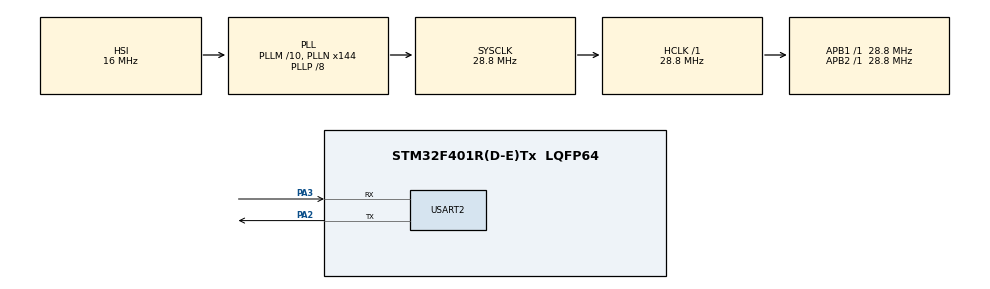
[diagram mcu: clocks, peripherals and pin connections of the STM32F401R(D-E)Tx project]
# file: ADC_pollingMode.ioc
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Mcu.Family=STM32F4
RCC.CortexFreq_Value=28800000
ADC1.Rank-0\#ChannelRegularConversion=1
VP_ADC1_TempSens_Input.Mode=IN-TempSens
ADC1.ContinuousConvMode=ENABLE
RCC.SYSCLKSource=RCC_SYSCLKSOURCE_PLLCLK
ProjectManager.StackSize=0x400
PA3.Mode=Asynchronous
ProjectManager.TargetToolchain=STM32CubeIDE
RCC.HCLKFreq_Value=28800000
RCC.APB2TimFreq_Value=28800000
RCC.LSE_VALUE=32768
RCC.AHBFreq_Value=28800000
ADC1.Channel-0\#ChannelRegularConversion=ADC_CHANNEL_TEMPSENSOR
RCC.HSE_VALUE=25000000
board=custom
RCC.VCOOutputFreq_Value=230400000
RCC.APB2Freq_Value=28800000
ADC1.NbrOfConversion=1
Mcu.Name=STM32F401R(D-E)Tx
ADC1.SamplingTime-0\#ChannelRegularConversion=ADC_SAMPLETIME_144CYCLES
PA2.Signal=USART2_TX
RCC.48MHZClocksFreq_Value=57600000
RCC.SYSCLKFreq_VALUE=28800000
Mcu.Package=LQFP64
ADC1.master=1
USART2.VirtualMode=VM_ASYNC
ProjectManager.HeapSize=0x200
RCC.HSI_VALUE=16000000
RCC.PLLP=RCC_PLLP_DIV8
NVIC.PriorityGroup=NVIC_PRIORITYGROUP_4
ADC1.NbrOfConversionFlag=1
RCC.PLLM=10
RCC.PLLN=144
RCC.APB1TimFreq_Value=28800000
PA2.Mode=Asynchronous
RCC.APB1Freq_Value=28800000
ADC1.EOCSelection=ADC_EOC_SEQ_CONV
ADC1.ClockPrescaler=ADC_CLOCK_SYNC_PCLK_DIV2
PA3.Signal=USART2_RX

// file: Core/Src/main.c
/* USER CODE BEGIN Header */
/**
  ******************************************************************************
  * @file           : main.c
  * @brief          : Main program body
  ******************************************************************************
  * @attention
  *
  * <h2><center>&copy; Copyright (c) 2021 STMicroelectronics.
  * All rights reserved.</center></h2>
  *
  * This software component is licensed by ST under BSD 3-Clause license,
  * the "License"; You may not use this file except in compliance with the
  * License. You may obtain a copy of the License at:
  *                        opensource.org/licenses/BSD-3-Clause
  *
  ******************************************************************************
  */
/* USER CODE END Header */
#include "main.h"

ADC_HandleTypeDef hadc1;

UART_HandleTypeDef huart2;

void SystemClock_Config(void);
static void MX_GPIO_Init(void);
static void MX_ADC1_Init(void);
static void MX_USART2_UART_Init(void);

int main(void)
{

  /* MCU Configuration--------------------------------------------------------*/

  /* Reset of all peripherals, Initializes the Flash interface and the Systick. */
  HAL_Init();

  /* Configure the system clock */
  SystemClock_Config();

  /* Initialize all configured peripherals */
  MX_GPIO_Init();
  MX_ADC1_Init();
  MX_USART2_UART_Init();
  /* USER CODE BEGIN 2 */
  HAL_ADC_Start(&hadc1);
  /* USER CODE END 2 */

  /* Infinite loop */
  while (1)
  {

    /* USER CODE BEGIN 3 */
	  char msg[20];
	      uint16_t rawValue;
	      float temp;

	      HAL_ADC_PollForConversion(&hadc1, HAL_MAX_DELAY);

	      rawValue = HAL_ADC_GetValue(&hadc1);
	      temp = ((float)rawValue) / 4095 * 3300;
	      temp = ((temp - 760.0) / 2.5) + 25;

	      sprintf(msg, "rawValue: %hu\r\n", rawValue);
	      HAL_UART_Transmit(&huart2, (uint8_t*) msg, strlen(msg), HAL_MAX_DELAY);

	      sprintf(msg, "Temperature: %f\r\n", temp);
	      HAL_UART_Transmit(&huart2, (uint8_t*) msg, strlen(msg), HAL_MAX_DELAY);
  }
  /* USER CODE END 3 */
}

void SystemClock_Config(void)
{
  RCC_OscInitTypeDef RCC_OscInitStruct = {0};
  RCC_ClkInitTypeDef RCC_ClkInitStruct = {0};

  /** Configure the main internal regulator output voltage
  */
  __HAL_RCC_PWR_CLK_ENABLE();
  __HAL_PWR_VOLTAGESCALING_CONFIG(PWR_REGULATOR_VOLTAGE_SCALE2);
  /** Initializes the RCC Oscillators according to the specified parameters
  * in the RCC_OscInitTypeDef structure.
  */
  RCC_OscInitStruct.OscillatorType = RCC_OSCILLATORTYPE_HSI;
  RCC_OscInitStruct.HSIState = RCC_HSI_ON;
  RCC_OscInitStruct.HSICalibrationValue = RCC_HSICALIBRATION_DEFAULT;
  RCC_OscInitStruct.PLL.PLLState = RCC_PLL_ON;
  RCC_OscInitStruct.PLL.PLLSource = RCC_PLLSOURCE_HSI;
  RCC_OscInitStruct.PLL.PLLM = 10;
  RCC_OscInitStruct.PLL.PLLN = 144;
  RCC_OscInitStruct.PLL.PLLP = RCC_PLLP_DIV8;
  RCC_OscInitStruct.PLL.PLLQ = 4;
  if (HAL_RCC_OscConfig(&RCC_OscInitStruct) != HAL_OK)
  {
    Error_Handler();
  }
  /** Initializes the CPU, AHB and APB buses clocks
  */
  RCC_ClkInitStruct.ClockType = RCC_CLOCKTYPE_HCLK|RCC_CLOCKTYPE_SYSCLK
                              |RCC_CLOCKTYPE_PCLK1|RCC_CLOCKTYPE_PCLK2;
  RCC_ClkInitStruct.SYSCLKSource = RCC_SYSCLKSOURCE_PLLCLK;
  RCC_ClkInitStruct.AHBCLKDivider = RCC_SYSCLK_DIV1;
  RCC_ClkInitStruct.APB1CLKDivider = RCC_HCLK_DIV1;
  RCC_ClkInitStruct.APB2CLKDivider = RCC_HCLK_DIV1;

  if (HAL_RCC_ClockConfig(&RCC_ClkInitStruct, FLASH_LATENCY_0) != HAL_OK)
  {
    Error_Handler();
  }
}

static void MX_ADC1_Init(void)
{

  ADC_ChannelConfTypeDef sConfig = {0};

  /** Configure the global features of the ADC (Clock, Resolution, Data Alignment and number of conversion)
  */
  hadc1.Instance = ADC1;
  hadc1.Init.ClockPrescaler = ADC_CLOCK_SYNC_PCLK_DIV2;
  hadc1.Init.Resolution = ADC_RESOLUTION_12B;
  hadc1.Init.ScanConvMode = DISABLE;
  hadc1.Init.ContinuousConvMode = ENABLE;
  hadc1.Init.DiscontinuousConvMode = DISABLE;
  hadc1.Init.ExternalTrigConvEdge = ADC_EXTERNALTRIGCONVEDGE_NONE;
  hadc1.Init.ExternalTrigConv = ADC_SOFTWARE_START;
  hadc1.Init.DataAlign = ADC_DATAALIGN_RIGHT;
  hadc1.Init.NbrOfConversion = 1;
  hadc1.Init.DMAContinuousRequests = DISABLE;
  hadc1.Init.EOCSelection = ADC_EOC_SEQ_CONV;
  if (HAL_ADC_Init(&hadc1) != HAL_OK)
  {
    Error_Handler();
  }
  /** Configure for the selected ADC regular channel its corresponding rank in the sequencer and its sample time.
  */
  sConfig.Channel = ADC_CHANNEL_TEMPSENSOR;
  sConfig.Rank = 1;
  sConfig.SamplingTime = ADC_SAMPLETIME_144CYCLES;
  if (HAL_ADC_ConfigChannel(&hadc1, &sConfig) != HAL_OK)
  {
    Error_Handler();
  }

}

static void MX_USART2_UART_Init(void)
{

  huart2.Instance = USART2;
  huart2.Init.BaudRate = 115200;
  huart2.Init.WordLength = UART_WORDLENGTH_8B;
  huart2.Init.StopBits = UART_STOPBITS_1;
  huart2.Init.Parity = UART_PARITY_NONE;
  huart2.Init.Mode = UART_MODE_TX_RX;
  huart2.Init.HwFlowCtl = UART_HWCONTROL_NONE;
  huart2.Init.OverSampling = UART_OVERSAMPLING_16;
  if (HAL_UART_Init(&huart2) != HAL_OK)
  {
    Error_Handler();
  }

}

static void MX_GPIO_Init(void)
{

  /* GPIO Ports Clock Enable */
  __HAL_RCC_GPIOA_CLK_ENABLE();

}

void Error_Handler(void)
{
  __disable_irq();
  while (1)
  {
  }
}

/************************ (C) COPYRIGHT STMicroelectronics *****END OF FILE****/
